AUTOSAR XML (schema 4-0-3)
package /ComponentTypes
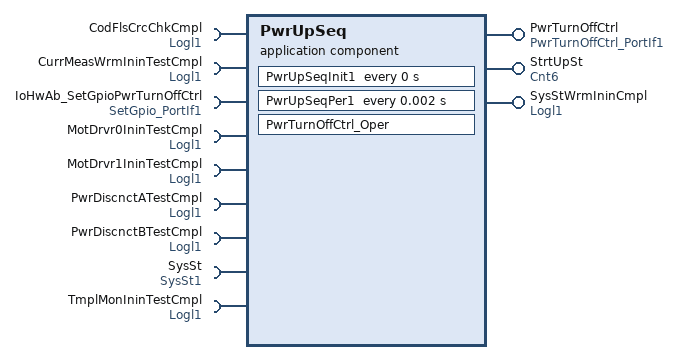
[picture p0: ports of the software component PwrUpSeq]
  application sw component type PwrUpSeq
    provide port PwrTurnOffCtrl: server-com-spec{operation=Oper, queue-length=1}, provided-interface=PwrTurnOffCtrl_PortIf1
    provide port StrtUpSt: nonqueued-sender-com-spec{data-element=Val, init-value=0}, provided-interface=Cnt6
    provide port SysStWrmIninCmpl: nonqueued-sender-com-spec{data-element=Logl, init-value=0}, provided-interface=Logl1
    9 x require port:
      CodFlsCrcChkCmpl: nonqueued-receiver-com-spec{data-element=Logl, filter=data-filter-type=ALWAYS, init-value=0}, required-interface=Logl1
      CurrMeasWrmIninTestCmpl: nonqueued-receiver-com-spec{data-element=Logl, filter=data-filter-type=ALWAYS, init-value=0}, required-interface=Logl1
      IoHwAb_SetGpioPwrTurnOffCtrl: required-interface=SetGpio_PortIf1
      MotDrvr0IninTestCmpl: nonqueued-receiver-com-spec{data-element=Logl, filter=data-filter-type=ALWAYS, init-value=0}, required-interface=Logl1
      MotDrvr1IninTestCmpl: nonqueued-receiver-com-spec{data-element=Logl, filter=data-filter-type=ALWAYS, init-value=0}, required-interface=Logl1
      PwrDiscnctATestCmpl: nonqueued-receiver-com-spec{data-element=Logl, filter=data-filter-type=ALWAYS, init-value=0}, required-interface=Logl1
      PwrDiscnctBTestCmpl: nonqueued-receiver-com-spec{data-element=Logl, filter=data-filter-type=ALWAYS, init-value=0}, required-interface=Logl1
      SysSt: nonqueued-receiver-com-spec{data-element=Val, filter=data-filter-type=ALWAYS, init-value=3}, required-interface=SysSt1
      TmplMonIninTestCmpl: nonqueued-receiver-com-spec{data-element=Logl, filter=data-filter-type=ALWAYS, init-value=0}, required-interface=Logl1
    behavior PwrUpSeq_InternalBehavior: data-type-mapping=Nexteer
      ar-typed-per-instance-memorys:
        data PwrTurnOffCtrlPrev: sw-calibration-access=READ-ONLY, type=uint8
      operation invoked event OIT_PwrTurnOffCtrl_Oper_PwrTurnOffCtrl_Oper: start-on-event=PwrTurnOffCtrl_Oper, operation=PwrTurnOffCtrl.Oper
      timing event PwrUpSeqInit1_InitEvent: start-on-event=PwrUpSeqInit1, period=0
      timing event TMT_PwrUpSeqPer1: start-on-event=PwrUpSeqPer1, period=0.002
      runnable PwrTurnOffCtrl_Oper
        sync call SC_IoHwAb_SetGpioPwrTurnOffCtrl_Oper: operation=IoHwAb_SetGpioPwrTurnOffCtrl.Oper, timeout=0
      runnable PwrUpSeqInit1
      runnable PwrUpSeqPer1
        data-receive-point-by-arguments:
          8 x access:
            REC_CodFlsCrcChkCmpl_Logl: accessed-variable=CodFlsCrcChkCmpl.Logl
            REC_CurrMeasWrmIninTestCmpl_Logl: accessed-variable=CurrMeasWrmIninTestCmpl.Logl
            REC_MotDrvr1IninTestCmpl_Logl: accessed-variable=MotDrvr1IninTestCmpl.Logl
            REC_MotDrvrIninTestCmpl_Logl: accessed-variable=MotDrvr0IninTestCmpl.Logl
            REC_PwrDiscnctATestCmpl_Logl: accessed-variable=PwrDiscnctATestCmpl.Logl
            REC_PwrDiscnctBTestCmpl_Logl: accessed-variable=PwrDiscnctBTestCmpl.Logl
            REC_SysSt_Val: accessed-variable=SysSt.Val
            REC_TmplMonIninTestCmpl_Logl: accessed-variable=TmplMonIninTestCmpl.Logl
        data-send-points:
          access SEND_StrtUpSt_Val: accessed-variable=StrtUpSt.Val
          access SEND_SysStWrmIninCmpl_Logl: accessed-variable=SysStWrmIninCmpl.Logl
  swc implementation PwrUpSeq_Implementation: behavior=PwrUpSeq_InternalBehavior
    code-descriptors:
      code Default: artifact-descriptors=autosar-engineering-object={short-label=Default, category=SWSRC}
